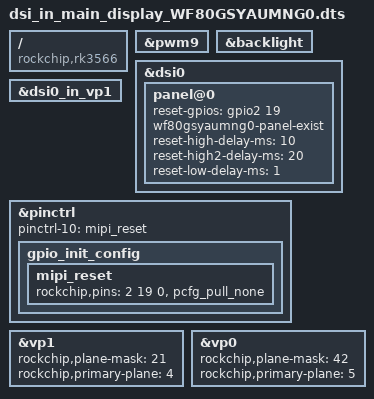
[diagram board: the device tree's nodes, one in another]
/dts-v1/;
/plugin/;
/ {
        compatible = "rockchip,rk3566";

        fragment@0 {
                target = <&pwm9>;
                __overlay__ {
                };
        };
        fragment@1 {
                target = <&backlight>;
                __overlay__ {
                };
        };
        fragment@2 {
                target = <&dsi0>;
                __overlay__ {
                        status = "okay";
                        panel@0 {
                                reset-gpios = <&gpio2 19 0>;
                                wf80gsyaumng0-panel-exist;
                                reset-high-delay-ms = <10>;
                                reset-high2-delay-ms = <20>;
                                reset-low-delay-ms = <1>;
                        };
                };
        };
        fragment@3 {
                target = <&dsi0_in_vp1>;
                __overlay__ {
                        status = "okay";
                };
        };
        fragment@4 {
                target = <&pinctrl>;
                __overlay__ {
                        pinctrl-10 = <&mipi_reset>;
                        gpio_init_config {
                                mipi_reset: mipi_reset {
                                        rockchip,pins =
                                                <2 19 0 &pcfg_pull_none>;
                                };
                        };
                };
        };
        fragment@5 {
                target = <&vp1>;
                __overlay__ {
					rockchip,plane-mask = <21>; //rockchip,plane-mask = <(1 << ROCKCHIP_VOP2_CLUSTER0 | 1 << ROCKCHIP_VOP2_SMART0 | 1 << ROCKCHIP_VOP2_ESMART0)>;
					rockchip,primary-plane = <4>; ///*rockchip,primary-plane = <ROCKCHIP_VOP2_SMART0>;*/
                };
        };
        fragment@6 {
                target = <&vp0>;
                __overlay__ {
					rockchip,plane-mask = <42>; //rockchip,plane-mask = <(1 << ROCKCHIP_VOP2_CLUSTER1 | 1 << ROCKCHIP_VOP2_SMART1 | 1 << ROCKCHIP_VOP2_ESMART1)>;
					rockchip,primary-plane = <5>; ///*rockchip,primary-plane = <ROCKCHIP_VOP2_SMART1>;*/
                };
        };
};
